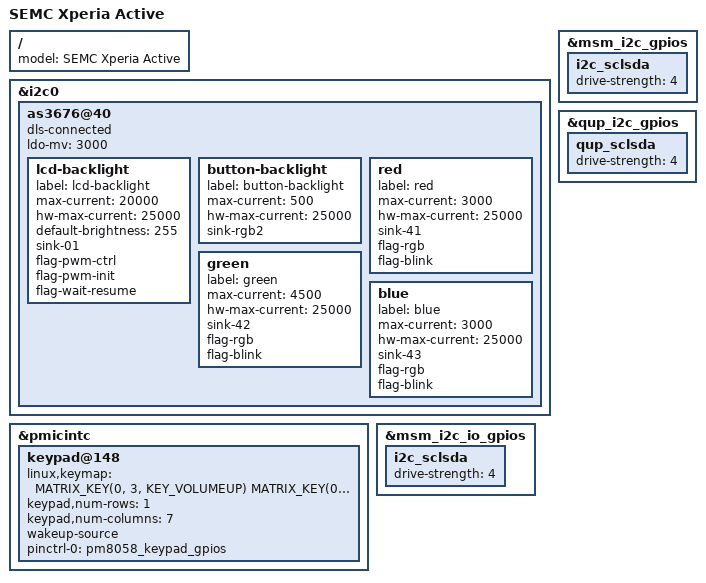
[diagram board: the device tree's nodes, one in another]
#include "qcom-msm7x30-semc-mogami.dtsi"

#include <dt-bindings/input/input.h>

/ {
	model = "SEMC Xperia Active";
};

&i2c0 {
	as3676@40 {
		dls-connected;

		ldo-mv = <3000>;

		lcd-backlight {
			label = "lcd-backlight";
			max-current = <20000>;
			hw-max-current = <25000>;
			default-brightness = <255>;
			sink-01;
			flag-pwm-ctrl;
			flag-pwm-init;
			flag-wait-resume;
		};

		button-backlight {
			label = "button-backlight";
			max-current = <500>;
			hw-max-current = <25000>;
			sink-rgb2;
		};

		red {
			label = "red";
			max-current = <3000>;
			hw-max-current = <25000>;
			sink-41;
			flag-rgb;
			flag-blink;
		};

		green {
			label = "green";
			max-current = <4500>;
			hw-max-current = <25000>;
			sink-42;
			flag-rgb;
			flag-blink;
		};

		blue {
			label = "blue";
			max-current = <3000>;
			hw-max-current = <25000>;
			sink-43;
			flag-rgb;
			flag-blink;
		};
	};
};

&pmicintc {
	keypad@148 {
		linux,keymap = <
			MATRIX_KEY(0, 3, KEY_VOLUMEUP)
			MATRIX_KEY(0, 4, KEY_VOLUMEDOWN)
			MATRIX_KEY(0, 5, KEY_CAMERA_FOCUS)
			MATRIX_KEY(0, 6, KEY_CAMERA)
			>;
		keypad,num-rows = <1>;
		keypad,num-columns = <7>;
		wakeup-source;

		pinctrl-names = "default";
		pinctrl-0 = <&pm8058_keypad_gpios>;
	};
};

&msm_i2c_gpios {
	i2c_sclsda {
		drive-strength = <4>;
	};
};

&msm_i2c_io_gpios {
	i2c_sclsda {
		drive-strength = <4>;
	};
};

&qup_i2c_gpios {
	qup_sclsda {
		drive-strength = <4>;
	};
};
